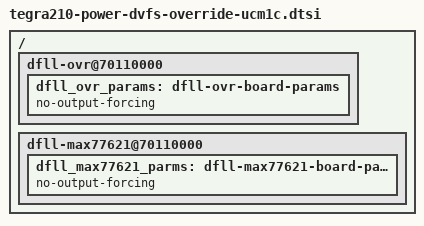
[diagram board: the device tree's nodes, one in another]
/*
 * Copyright (c) 2015 NVIDIA CORPORATION. All rights reserved.
 *
 * This software is licensed under the terms of the GNU General Public
 * License version 2, as published by the Free Software Foundation, and
 * may be copied, distributed, and modified under those terms.
 *
 * This program is distributed in the hope that it will be useful,
 * but WITHOUT ANY WARRANTY; without even the implied warranty of
 * MERCHANTABILITY or FITNESS FOR A PARTICULAR PURPOSE.  See the
 * GNU General Public License for more details.
 *
 */

/*
 * DVFS overrides for T210 sku 0x7/0x17 UCM1 (4/4/16) personality in commercial
 * temperature range.
 *
 * Recommended to copy the contents of this file to final .dts file for
 * the respective platform. If file is included "as is", the #include statement
 * should be placed after .dtsi with dvfs_rail node definition is included.
 */

/ {
	dfll-ovr@70110000 {
		dfll_ovr_params: dfll-ovr-board-params {
			/delete-property/ fixed-output-forcing;
			no-output-forcing;
		};
	};

	dfll-max77621@70110000 {
		dfll_max77621_parms: dfll-max77621-board-params {
			/delete-property/ fixed-output-forcing;
			no-output-forcing;
		};
	};
};


